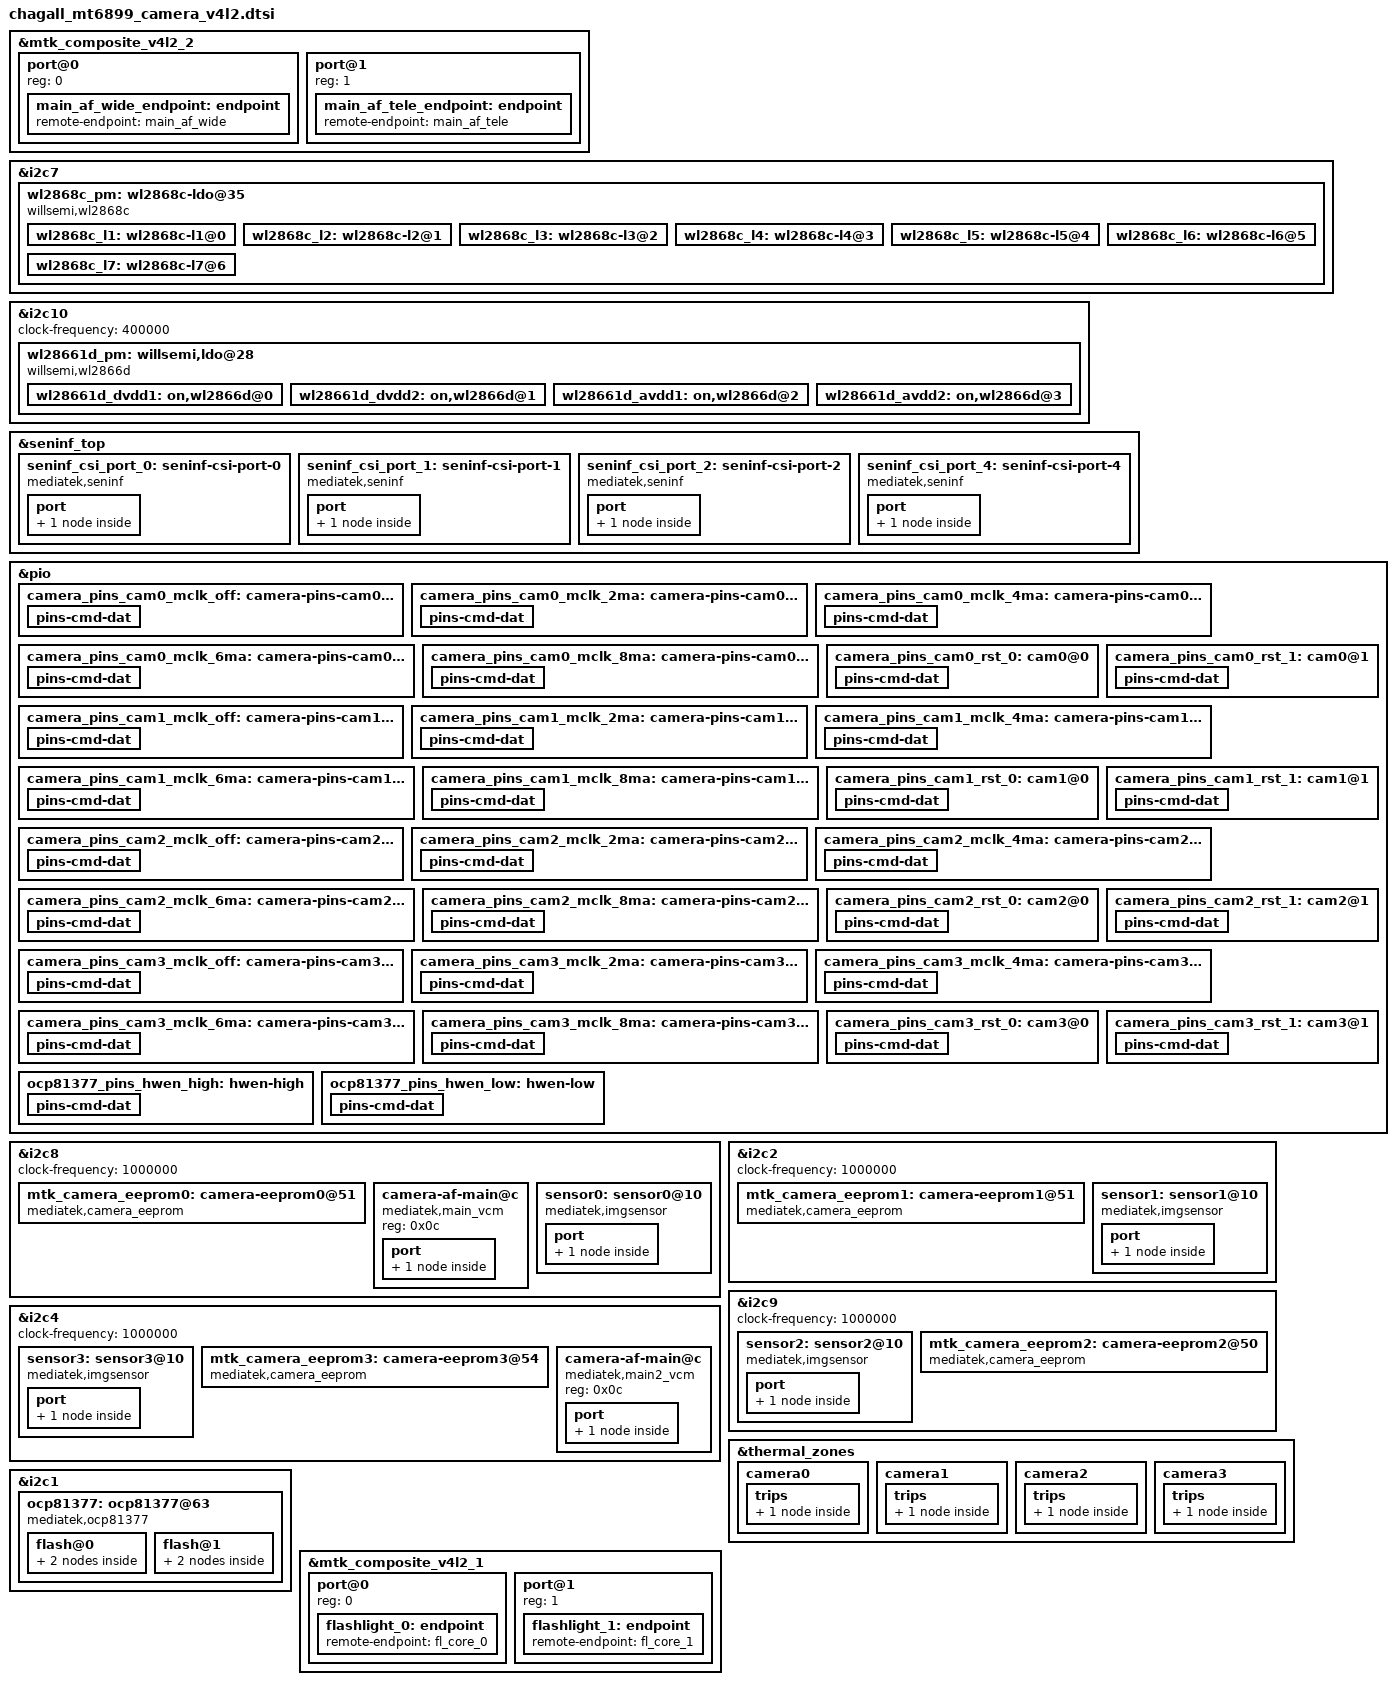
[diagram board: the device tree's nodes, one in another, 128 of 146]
// SPDX-License-Identifier: GPL-2.0
/* Copyright (c) 2023 MediaTek Inc. */
#include <dt-bindings/clock/mt6899-clk.h>


&mtk_composite_v4l2_2 {
	#address-cells = <1>;
	#size-cells = <0>;
	port@0 {
		reg = <0>;
		main_af_wide_endpoint: endpoint {
			remote-endpoint = <&main_af_wide>;
		};
	};
	port@1 {
		reg = <1>;
		main_af_tele_endpoint: endpoint {
			remote-endpoint = <&main_af_tele>;
		};
    };
};

&i2c7 {
	status = "okay";
	wl2868c_pm:wl2868c-ldo@35 {
		compatible = "willsemi,wl2868c";
		reg = <0x2f>;/*slave address*/
		index = <0>;

		wl2868c_l1:wl2868c-l1@0{
			offset = /bits/ 16 <0x0000>;
			regulator-name ="ldo1";
			regulator-min-microvolt = <528000>;
			regulator-max-microvolt = <1504000>;
			min-dropout-voltage = <225000>;
			init-voltage = <1100000>;
			iout_ua = <650000>;
		};

		wl2868c_l2:wl2868c-l2@1{
			offset = /bits/ 16 <0x0001>;
			regulator-name ="ldo2";
			regulator-min-microvolt = <528000>;
			regulator-max-microvolt = <1504000>;
			min-dropout-voltage = <225000>;
			init-voltage = <1050000>;
			iout_ua = <650000>;
		};

		wl2868c_l3:wl2868c-l3@2{
			offset = /bits/ 16 <0x0002>;
			regulator-name ="ldo3";
			regulator-min-microvolt = <1504000>;
			regulator-max-microvolt = <3400000>;
			min-dropout-voltage = <200000>;
			init-voltage = <3100000>;
			iout_ua = <650000>;
		};

		wl2868c_l4:wl2868c-l4@3{
			offset = /bits/ 16 <0x0003>;
			regulator-name ="ldo4";
			regulator-min-microvolt = <1504000>;
			regulator-max-microvolt = <3400000>;
			min-dropout-voltage = <200000>;
			init-voltage = <2800000>;
			iout_ua = <650000>;
		};

		wl2868c_l5:wl2868c-l5@4{
			offset = /bits/ 16 <0x0004>;
			regulator-name ="ldo5";
			regulator-min-microvolt = <1504000>;
			regulator-max-microvolt = <3400000>;
			min-dropout-voltage = <300000>;
			init-voltage = <3300000>;
			iout_ua = <650000>;
		};

		wl2868c_l6:wl2868c-l6@5{
			offset = /bits/ 16 <0x0005>;
			regulator-name ="ldo6";
			regulator-min-microvolt = <1504000>;
			regulator-max-microvolt = <3400000>;
			min-dropout-voltage = <300000>;
			init-voltage = <3100000>;
			iout_ua = <650000>;
		};

		wl2868c_l7:wl2868c-l7@6{
			offset = /bits/ 16 <0x0006>;
			regulator-name ="ldo7";
			regulator-min-microvolt = <1504000>;
			regulator-max-microvolt = <3400000>;
			min-dropout-voltage = <300000>;
			init-voltage = <3300000>;
			iout_ua = <650000>;
		};
	};
};

&i2c10 {
	status = "okay";
	clock-frequency = <400000>;
	wl28661d_pm:willsemi,ldo@28 {
		compatible = "willsemi,wl2866d";
		reg = <0x28>;
		index = <0>;
		wl28661d_dvdd1:on,wl2866d@0{
			offset = /bits/ 16 <0x0000>;
			regulator-name ="dvdd1";
			regulator-min-microvolt = <600000>;
			regulator-max-microvolt = <1800000>;
			min-dropout-voltage = <80000>;
			iout_ua = <500000>;
			init-voltage = <1200000>;
		};
		wl28661d_dvdd2:on,wl2866d@1{
			offset = /bits/ 16 <0x0001>;
			regulator-name ="dvdd2";
			regulator-min-microvolt = <600000>;
			regulator-max-microvolt = <1800000>;
			min-dropout-voltage = <80000>;
			iout_ua = <500000>;
			init-voltage = <1000000>;
		};
		wl28661d_avdd1:on,wl2866d@2{
			offset = /bits/ 16 <0x0002>;
			regulator-name ="avdd1";
			regulator-min-microvolt = <1200000>;
			regulator-max-microvolt = <4300000>;
			min-dropout-voltage = <90000>;
			iout_ua = <300000>;
			init-voltage = <2800000>;
		};
		wl28661d_avdd2:on,wl2866d@3{
			offset = /bits/ 16 <0x0003>;
			regulator-name ="avdd2";
			regulator-min-microvolt = <1200000>;
			regulator-max-microvolt = <4300000>;
			min-dropout-voltage = <90000>;
			iout_ua = <300000>;
			init-voltage = <2200000>;
		};
	};
};

&seninf_top {
	seninf_csi_port_0: seninf-csi-port-0 {
		compatible = "mediatek,seninf";
		csi-port = "0";

		nvmem-cells = <&csi_efuse0>;
		nvmem-cell-names = "rg_csi";

		port {
			seninf_csi_port_0_in: endpoint {
				remote-endpoint = <&sensor1_out>;
			};
		};
	};
	seninf_csi_port_1: seninf-csi-port-1 {
			compatible = "mediatek,seninf";
			csi-port = "1";

			nvmem-cells = <&csi_efuse1>;
			nvmem-cell-names = "rg_csi";

			port {
				seninf_csi_port_1_in: endpoint {
					remote-endpoint = <&sensor2_out>;
				};
			};
	};
	seninf_csi_port_2: seninf-csi-port-2 {
		compatible = "mediatek,seninf";
		csi-port = "2";

		nvmem-cells = <&csi_efuse2>;
		nvmem-cell-names = "rg_csi";

		port {
			seninf_csi_port_2_in: endpoint {
				remote-endpoint = <&sensor3_out>;
			};
		};
	};
	seninf_csi_port_4: seninf-csi-port-4 {
		compatible = "mediatek,seninf";
		csi-port = "4";

		nvmem-cells = <&csi_efuse4>;
		nvmem-cell-names = "rg_csi";

		port {
			seninf_csi_port_4_in: endpoint {
				remote-endpoint = <&sensor0_out>;
			};
		};
	};
};

/* CAMERA GPIO standardization */
&pio {
	camera_pins_cam0_mclk_off: camera-pins-cam0-mclk-off {
		pins-cmd-dat {
			pinmux = <PINMUX_GPIO126__FUNC_GPIO126>;
			drive-strength = <1>;
		};
	};
	camera_pins_cam0_mclk_2ma: camera-pins-cam0-mclk-2ma {
		pins-cmd-dat {
			pinmux = <PINMUX_GPIO126__FUNC_CMMCLK3>;
			drive-strength = <0>;
		};
	};
	camera_pins_cam0_mclk_4ma: camera-pins-cam0-mclk-4ma {
		pins-cmd-dat {
			pinmux = <PINMUX_GPIO126__FUNC_CMMCLK3>;
			drive-strength = <1>;
		};
	};
	camera_pins_cam0_mclk_6ma: camera-pins-cam0-mclk-6ma {
		pins-cmd-dat {
			pinmux = <PINMUX_GPIO126__FUNC_CMMCLK3>;
			drive-strength = <2>;
		};
	};
	camera_pins_cam0_mclk_8ma: camera-pins-cam0-mclk-8ma {
		pins-cmd-dat {
			pinmux = <PINMUX_GPIO126__FUNC_CMMCLK3>;
			drive-strength = <3>;
		};
	};
	camera_pins_cam0_rst_0: cam0@0 {
		pins-cmd-dat {
			pinmux = <PINMUX_GPIO117__FUNC_GPIO117>;
			drive-strength = <0>;
			output-low;
		};
	};
	camera_pins_cam0_rst_1: cam0@1 {
		pins-cmd-dat {
			pinmux = <PINMUX_GPIO117__FUNC_GPIO117>;
			drive-strength = <1>;
			output-high;
		};
	};

	camera_pins_cam1_mclk_off: camera-pins-cam1-mclk-off {
		pins-cmd-dat {
			pinmux = <PINMUX_GPIO123__FUNC_GPIO123>;
			drive-strength = <1>;
		};
	};
	camera_pins_cam1_mclk_2ma: camera-pins-cam1-mclk-2ma {
		pins-cmd-dat {
			pinmux = <PINMUX_GPIO123__FUNC_CMMCLK0>;
			drive-strength = <0>;
		};
	};
	camera_pins_cam1_mclk_4ma: camera-pins-cam1-mclk-4ma {
		pins-cmd-dat {
			pinmux = <PINMUX_GPIO123__FUNC_CMMCLK0>;
			drive-strength = <1>;
		};
	};
	camera_pins_cam1_mclk_6ma: camera-pins-cam1-mclk-6ma {
		pins-cmd-dat {
			pinmux = <PINMUX_GPIO123__FUNC_CMMCLK0>;
			drive-strength = <2>;
		};
	};
	camera_pins_cam1_mclk_8ma: camera-pins-cam1-mclk-8ma {
		pins-cmd-dat {
			pinmux = <PINMUX_GPIO123__FUNC_CMMCLK0>;
			drive-strength = <3>;
		};
	};
	camera_pins_cam1_rst_0: cam1@0 {
		pins-cmd-dat {
			pinmux = <PINMUX_GPIO115__FUNC_GPIO115>;
			slew-rate = <1>;
			output-low;
		};
	};
	camera_pins_cam1_rst_1: cam1@1 {
		pins-cmd-dat {
			pinmux = <PINMUX_GPIO115__FUNC_GPIO115>;
			slew-rate = <1>;
			output-high;
		};
	};

	camera_pins_cam2_mclk_off: camera-pins-cam2-mclk-off {
		pins-cmd-dat {
			pinmux = <PINMUX_GPIO125__FUNC_GPIO125>;
			drive-strength = <1>;
		};
	};
	camera_pins_cam2_mclk_2ma: camera-pins-cam2-mclk-2ma {
		pins-cmd-dat {
			pinmux = <PINMUX_GPIO125__FUNC_CMMCLK2>;
			drive-strength = <0>;
		};
	};
	camera_pins_cam2_mclk_4ma: camera-pins-cam2-mclk-4ma {
		pins-cmd-dat {
			pinmux = <PINMUX_GPIO125__FUNC_CMMCLK2>;
			drive-strength = <1>;
		};
	};
	camera_pins_cam2_mclk_6ma: camera-pins-cam2-mclk-6ma {
		pins-cmd-dat {
			pinmux = <PINMUX_GPIO125__FUNC_CMMCLK2>;
			drive-strength = <2>;
		};
	};
	camera_pins_cam2_mclk_8ma: camera-pins-cam2-mclk-8ma {
		pins-cmd-dat {
			pinmux = <PINMUX_GPIO125__FUNC_CMMCLK2>;
			drive-strength = <3>;
		};
	};
	camera_pins_cam2_rst_0: cam2@0 {
		pins-cmd-dat {
			pinmux = <PINMUX_GPIO118__FUNC_GPIO118>;
			slew-rate = <1>;
			output-low;
		};
	};
	camera_pins_cam2_rst_1: cam2@1 {
		pins-cmd-dat {
			pinmux = <PINMUX_GPIO118__FUNC_GPIO118>;
			slew-rate = <1>;
			output-high;
		};
	};

	camera_pins_cam3_mclk_off: camera-pins-cam3-mclk-off {
		pins-cmd-dat {
			pinmux = <PINMUX_GPIO124__FUNC_GPIO124>;
			drive-strength = <1>;
		};
	};
	camera_pins_cam3_mclk_2ma: camera-pins-cam3-mclk-2ma {
		pins-cmd-dat {
			pinmux = <PINMUX_GPIO124__FUNC_CMMCLK1>;
			drive-strength = <0>;
		};
	};
	camera_pins_cam3_mclk_4ma: camera-pins-cam3-mclk-4ma {
		pins-cmd-dat {
			pinmux = <PINMUX_GPIO124__FUNC_CMMCLK1>;
			drive-strength = <1>;
		};
	};
	camera_pins_cam3_mclk_6ma: camera-pins-cam3-mclk-6ma {
		pins-cmd-dat {
			pinmux = <PINMUX_GPIO124__FUNC_CMMCLK1>;
			drive-strength = <2>;
		};
	};
	camera_pins_cam3_mclk_8ma: camera-pins-cam3-mclk-8ma {
		pins-cmd-dat {
			pinmux = <PINMUX_GPIO124__FUNC_CMMCLK1>;
			drive-strength = <3>;
		};
	};
	camera_pins_cam3_rst_0: cam3@0 {
		pins-cmd-dat {
			pinmux = <PINMUX_GPIO116__FUNC_GPIO116>;
			slew-rate = <1>;
			output-low;
		};
	};
	camera_pins_cam3_rst_1: cam3@1 {
		pins-cmd-dat {
			pinmux = <PINMUX_GPIO116__FUNC_GPIO116>;
			slew-rate = <1>;
			output-high;
		};
	};
};
/* CAMERA GPIO end */

&i2c8 {
	status = "okay";
	clock-frequency = <1000000>;

	mtk_camera_eeprom0:camera-eeprom0@51 {
		compatible = "mediatek,camera_eeprom";
		reg = <0x51>;
		names = "chagallovx8000wide_mtk_eeprom_sunny";
		status = "okay";
	};

	camera-af-main@c {
		compatible = "mediatek,main_vcm";
		reg = <0x0c>;
		port {
			main_af_wide: endpoint {
				remote-endpoint = <&main_af_wide_endpoint>;
			};
		};
	};

	sensor0: sensor0@10 {
		compatible = "mediatek,imgsensor";
		sensor-names = "chagallovx8000wide_mipi_raw";
		reg = <0x10>;

		#thermal-sensor-cells = <0>;

		pinctrl-names = "mclk_off",
				"mclk_2mA",
				"mclk_4mA",
				"mclk_6mA",
				"mclk_8mA",
				"rst_low",
				"rst_high";
		pinctrl-0 = <&camera_pins_cam0_mclk_off>;
		pinctrl-1 = <&camera_pins_cam0_mclk_2ma>;
		pinctrl-2 = <&camera_pins_cam0_mclk_4ma>;
		pinctrl-3 = <&camera_pins_cam0_mclk_6ma>;
		pinctrl-4 = <&camera_pins_cam0_mclk_8ma>;
		pinctrl-5 = <&camera_pins_cam0_rst_0>;
		pinctrl-6 = <&camera_pins_cam0_rst_1>;

		avdd-supply = <&wl2868c_l4>;
		dvdd-supply = <&wl2868c_l1>;
		dovdd-supply = <&mt6368_vio28>;
		afvdd-supply = <&wl2868c_l3>;

		clocks = <&topckgen_clk CLK_TOP_UNIVPLL_192M_D32>,
			<&topckgen_clk CLK_TOP_UNIVPLL_192M_D16>,
			<&topckgen_clk CLK_TOP_F26M_CK_D2>,
			<&topckgen_clk CLK_TOP_UNIVPLL_192M_D10>,
			<&topckgen_clk CLK_TOP_UNIVPLL_192M_D8>,
			<&topckgen_clk CLK_TOP_UNIVPLL_D6_D16>,
			<&topckgen_clk CLK_TOP_UNIVPLL_D6_D8>,
			<&vlp_cksys_clk CLK_VLP_CK_CAMTG3_SEL>;
		clock-names = "6", "12", "13", "19.2", "24", "26", "52", "mclk";

		status = "okay";
		port {
			sensor0_out: endpoint {
				remote-endpoint = <&seninf_csi_port_4_in>;
			};
		};
	};
};

&i2c2 {
	status = "okay";
	clock-frequency = <1000000>;

	mtk_camera_eeprom1:camera-eeprom1@51 {
		compatible = "mediatek,camera_eeprom";
		reg = <0x51>;
                names = "chagall5kkdsfront_mtk_eeprom_ofilm";
		status = "okay";
	};

	sensor1: sensor1@10 {
		compatible = "mediatek,imgsensor";
		sensor-names = "chagalls5kkdsfront_mipi_raw";
		reg = <0x10>;

		#thermal-sensor-cells = <0>;

		pinctrl-names = "mclk_off",
				"mclk_2mA",
				"mclk_4mA",
				"mclk_6mA",
				"mclk_8mA",
				"rst_low",
				"rst_high";
		pinctrl-0 = <&camera_pins_cam1_mclk_off>;
		pinctrl-1 = <&camera_pins_cam1_mclk_2ma>;
		pinctrl-2 = <&camera_pins_cam1_mclk_4ma>;
		pinctrl-3 = <&camera_pins_cam1_mclk_6ma>;
		pinctrl-4 = <&camera_pins_cam1_mclk_8ma>;
		pinctrl-5 = <&camera_pins_cam1_rst_0>;
		pinctrl-6 = <&camera_pins_cam1_rst_1>;

		avdd-supply = <&wl2868c_l6>;
		dvdd-supply = <&wl2868c_l2>;
		dovdd-supply = <&mt6368_vio28>;

		clocks = <&topckgen_clk CLK_TOP_UNIVPLL_192M_D32>,
			<&topckgen_clk CLK_TOP_UNIVPLL_192M_D16>,
			<&topckgen_clk CLK_TOP_F26M_CK_D2>,
			<&topckgen_clk CLK_TOP_UNIVPLL_192M_D10>,
			<&topckgen_clk CLK_TOP_UNIVPLL_192M_D8>,
			<&topckgen_clk CLK_TOP_UNIVPLL_D6_D16>,
			<&topckgen_clk CLK_TOP_UNIVPLL_D6_D8>,
			<&vlp_cksys_clk CLK_VLP_CK_CAMTG0_SEL>;
		clock-names = "6", "12", "13", "19.2", "24", "26", "52", "mclk";

		status = "okay";
		port {
			sensor1_out: endpoint {
				remote-endpoint = <&seninf_csi_port_0_in>;
			};
		};
	};
};

&i2c9 {
	status = "okay";
	clock-frequency = <1000000>;

	sensor2: sensor2@10 {
		compatible = "mediatek,imgsensor";
		sensor-names = "chagallov13bultra_mipi_raw";
		reg = <0x10>;

		#thermal-sensor-cells = <0>;

		pinctrl-names = "mclk_off",
				"mclk_2mA",
				"mclk_4mA",
				"mclk_6mA",
				"mclk_8mA",
				"rst_low",
				"rst_high";
		pinctrl-0 = <&camera_pins_cam2_mclk_off>;
		pinctrl-1 = <&camera_pins_cam2_mclk_2ma>;
		pinctrl-2 = <&camera_pins_cam2_mclk_4ma>;
		pinctrl-3 = <&camera_pins_cam2_mclk_6ma>;
		pinctrl-4 = <&camera_pins_cam2_mclk_8ma>;
		pinctrl-5 = <&camera_pins_cam2_rst_0>;
		pinctrl-6 = <&camera_pins_cam2_rst_1>;

		avdd-supply = <&wl28661d_avdd1>;
		dvdd-supply = <&wl28661d_dvdd1>;
		dovdd-supply = <&mt6368_vio28>;

		clocks = <&topckgen_clk CLK_TOP_UNIVPLL_192M_D32>,
			<&topckgen_clk CLK_TOP_UNIVPLL_192M_D16>,
			<&topckgen_clk CLK_TOP_F26M_CK_D2>,
			<&topckgen_clk CLK_TOP_UNIVPLL_192M_D10>,
			<&topckgen_clk CLK_TOP_UNIVPLL_192M_D8>,
			<&topckgen_clk CLK_TOP_UNIVPLL_D6_D16>,
			<&topckgen_clk CLK_TOP_UNIVPLL_D6_D8>,
			<&vlp_cksys_clk CLK_VLP_CK_CAMTG2_SEL>;
		clock-names = "6", "12", "13", "19.2", "24", "26", "52", "mclk";

		status = "okay";
		port {
			sensor2_out: endpoint {
				remote-endpoint = <&seninf_csi_port_1_in>;
			};
		};
	};

	mtk_camera_eeprom2:camera-eeprom2@50 {
		compatible = "mediatek,camera_eeprom";
		reg = <0x50>;
		names = "chagallov13bultra_mtk_eeprom_ofilm";
		status = "okay";
	};
};

&i2c4 {
	status = "okay";
	clock-frequency = <1000000>;
	sensor3: sensor3@10 {
		compatible = "mediatek,imgsensor";
		sensor-names = "chagalls5kjn5tele_mipi_raw";
		reg = <0x10>;
		#thermal-sensor-cells = <0>;
		pinctrl-names = "mclk_off",
				"mclk_2mA",
				"mclk_4mA",
				"mclk_6mA",
				"mclk_8mA",
				"rst_low",
				"rst_high";
		pinctrl-0 = <&camera_pins_cam3_mclk_off>;
		pinctrl-1 = <&camera_pins_cam3_mclk_2ma>;
		pinctrl-2 = <&camera_pins_cam3_mclk_4ma>;
		pinctrl-3 = <&camera_pins_cam3_mclk_6ma>;
		pinctrl-4 = <&camera_pins_cam3_mclk_8ma>;
		pinctrl-5 = <&camera_pins_cam3_rst_0>;
		pinctrl-6 = <&camera_pins_cam3_rst_1>;

		dvdd-supply = <&wl28661d_dvdd2>;
		avdd-supply = <&wl28661d_avdd2>;
		dovdd-supply = <&mt6368_vio28>;
		afvdd-supply = <&wl2868c_l5>;

		clocks = <&topckgen_clk CLK_TOP_UNIVPLL_192M_D32>,
			<&topckgen_clk CLK_TOP_UNIVPLL_192M_D16>,
			<&topckgen_clk CLK_TOP_F26M_CK_D2>,
			<&topckgen_clk CLK_TOP_UNIVPLL_192M_D10>,
			<&topckgen_clk CLK_TOP_UNIVPLL_192M_D8>,
			<&topckgen_clk CLK_TOP_UNIVPLL_D6_D16>,
			<&topckgen_clk CLK_TOP_UNIVPLL_D6_D8>,
			<&vlp_cksys_clk CLK_VLP_CK_CAMTG1_SEL>;
		clock-names = "6", "12", "13", "19.2", "24", "26", "52", "mclk";
		status = "okay";
		port {
			sensor3_out: endpoint {
				remote-endpoint = <&seninf_csi_port_2_in>;
			};
		};
	};

	mtk_camera_eeprom3:camera-eeprom3@54 {
		compatible = "mediatek,camera_eeprom";
		reg = <0x54>;
		names = "chagall5kjn5tele_mtk_eeprom_semco";
		status = "okay";
	};

	camera-af-main@c {
		compatible = "mediatek,main2_vcm";
		reg = <0x0c>;
		port {
			main_af_tele: endpoint {
				remote-endpoint = <&main_af_tele_endpoint>;
			};
		};
	};
};

&thermal_zones {
	camera0: camera0 {
		polling-delay = <0>;
		polling-delay-passive = <0>;
		thermal-sensors = <&sensor0>;
		trips {
			camera0_crit: camera0-crit {
				temperature = <120000>;
				hysteresis = <2000>;
				type = "passive";
			};
		};
	};
	camera1: camera1 {
		polling-delay = <0>;
		polling-delay-passive = <0>;
		thermal-sensors = <&sensor1>;
		trips {
			camera1_crit: camera1-crit {
				temperature = <120000>;
				hysteresis = <2000>;
				type = "passive";
			};
		};
	};
	camera2: camera2 {
		polling-delay = <0>;
		polling-delay-passive = <0>;
		thermal-sensors = <&sensor2>;
		trips {
			camera2_crit: camera2-crit {
				temperature = <120000>;
				hysteresis = <2000>;
				type = "passive";
			};
		};
	};
	camera3: camera3 {
		polling-delay = <0>;
		polling-delay-passive = <0>;
		thermal-sensors = <&sensor3>;
		trips {
			camera3_crit: camera3-crit {
				temperature = <120000>;
				hysteresis = <2000>;
				type = "passive";
			};
		};
	};
};

&i2c1 {
	#address-cells = <1>;
	#size-cells = <0>;
	ocp81377:ocp81377@63 {
		compatible = "mediatek,ocp81377";
		#address-cells = <1>;
		#size-cells = <0>;
		reg = <0x63>;
		#cooling-cells = <2>;
		pinctrl-names = "hwen-high", "hwen-low";
		pinctrl-0 = <&ocp81377_pins_hwen_high>;
		pinctrl-1 = <&ocp81377_pins_hwen_low>;
		status = "okay";
		flash@0{
			reg = <0>;
			type = <0>;
			ct = <0>;
			part = <0>;
			port {
				fl_core_0: endpoint {
					remote-endpoint = <&flashlight_0>;
				};
			};
		};
		flash@1{
			reg = <1>;
			type = <0>;
			ct = <1>;
			part = <0>;
			port {
				fl_core_1: endpoint {
					remote-endpoint = <&flashlight_1>;
				};
			};
		};
	};
};

&pio {
	ocp81377_pins_hwen_high: hwen-high {
		pins-cmd-dat {
			pinmux = <PINMUX_GPIO62__FUNC_GPIO62>;
			slew-rate = <1>;
			output-high;
		};
	};

	ocp81377_pins_hwen_low: hwen-low {
		pins-cmd-dat {
			pinmux = <PINMUX_GPIO62__FUNC_GPIO62>;
			slew-rate = <1>;
			output-low;
		};
	};
};

&mtk_composite_v4l2_1 {
	#address-cells = <1>;
	#size-cells = <0>;
	port@0 {
		reg = <0>;
		flashlight_0: endpoint {
			remote-endpoint = <&fl_core_0>;
		};
	};
	port@1 {
		reg = <1>;
		flashlight_1: endpoint {
			remote-endpoint = <&fl_core_1>;
		};
	};
};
